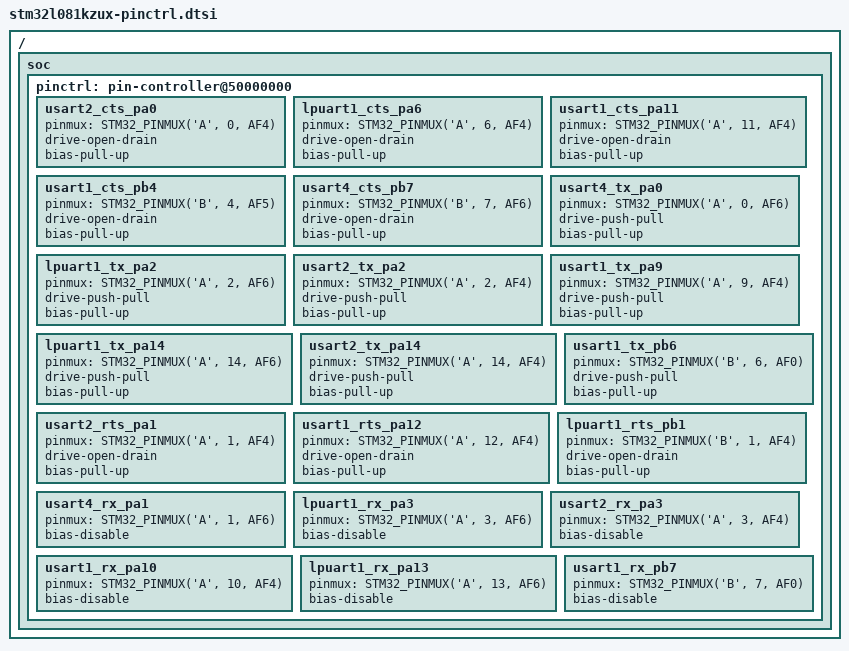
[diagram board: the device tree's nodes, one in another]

/*
 * NOTE: Autogenerated file using stm32_pinctrl_gen.py
 *
 * SPDX-License-Identifier: Apache-2.0
 */

#include <dt-bindings/pinctrl/stm32-pinctrl.h>

/ {
	soc {
		pinctrl: pin-controller@50000000 {
			/* UART_CTS */
			usart2_cts_pa0: usart2_cts_pa0 {
				pinmux = <STM32_PINMUX('A', 0, AF4)>;
				drive-open-drain;
				bias-pull-up;
			};

			lpuart1_cts_pa6: lpuart1_cts_pa6 {
				pinmux = <STM32_PINMUX('A', 6, AF4)>;
				drive-open-drain;
				bias-pull-up;
			};

			lpuart1_cts_pa6: lpuart1_cts_pa6 {
				pinmux = <STM32_PINMUX('A', 6, AF4)>;
				drive-open-drain;
				bias-pull-up;
			};

			usart1_cts_pa11: usart1_cts_pa11 {
				pinmux = <STM32_PINMUX('A', 11, AF4)>;
				drive-open-drain;
				bias-pull-up;
			};

			usart1_cts_pb4: usart1_cts_pb4 {
				pinmux = <STM32_PINMUX('B', 4, AF5)>;
				drive-open-drain;
				bias-pull-up;
			};

			usart4_cts_pb7: usart4_cts_pb7 {
				pinmux = <STM32_PINMUX('B', 7, AF6)>;
				drive-open-drain;
				bias-pull-up;
			};


			/* UART_TX */
			usart4_tx_pa0: usart4_tx_pa0 {
				pinmux = <STM32_PINMUX('A', 0, AF6)>;
				drive-push-pull;
				bias-pull-up;
			};

			lpuart1_tx_pa2: lpuart1_tx_pa2 {
				pinmux = <STM32_PINMUX('A', 2, AF6)>;
				drive-push-pull;
				bias-pull-up;
			};

			lpuart1_tx_pa2: lpuart1_tx_pa2 {
				pinmux = <STM32_PINMUX('A', 2, AF6)>;
				drive-push-pull;
				bias-pull-up;
			};

			usart2_tx_pa2: usart2_tx_pa2 {
				pinmux = <STM32_PINMUX('A', 2, AF4)>;
				drive-push-pull;
				bias-pull-up;
			};

			usart1_tx_pa9: usart1_tx_pa9 {
				pinmux = <STM32_PINMUX('A', 9, AF4)>;
				drive-push-pull;
				bias-pull-up;
			};

			lpuart1_tx_pa14: lpuart1_tx_pa14 {
				pinmux = <STM32_PINMUX('A', 14, AF6)>;
				drive-push-pull;
				bias-pull-up;
			};

			lpuart1_tx_pa14: lpuart1_tx_pa14 {
				pinmux = <STM32_PINMUX('A', 14, AF6)>;
				drive-push-pull;
				bias-pull-up;
			};

			usart2_tx_pa14: usart2_tx_pa14 {
				pinmux = <STM32_PINMUX('A', 14, AF4)>;
				drive-push-pull;
				bias-pull-up;
			};

			usart1_tx_pb6: usart1_tx_pb6 {
				pinmux = <STM32_PINMUX('B', 6, AF0)>;
				drive-push-pull;
				bias-pull-up;
			};


			/* UART_RTS */
			usart2_rts_pa1: usart2_rts_pa1 {
				pinmux = <STM32_PINMUX('A', 1, AF4)>;
				drive-open-drain;
				bias-pull-up;
			};

			usart1_rts_pa12: usart1_rts_pa12 {
				pinmux = <STM32_PINMUX('A', 12, AF4)>;
				drive-open-drain;
				bias-pull-up;
			};

			lpuart1_rts_pb1: lpuart1_rts_pb1 {
				pinmux = <STM32_PINMUX('B', 1, AF4)>;
				drive-open-drain;
				bias-pull-up;
			};

			lpuart1_rts_pb1: lpuart1_rts_pb1 {
				pinmux = <STM32_PINMUX('B', 1, AF4)>;
				drive-open-drain;
				bias-pull-up;
			};


			/* UART_RX */
			usart4_rx_pa1: usart4_rx_pa1 {
				pinmux = <STM32_PINMUX('A', 1, AF6)>;
				bias-disable;
			};

			lpuart1_rx_pa3: lpuart1_rx_pa3 {
				pinmux = <STM32_PINMUX('A', 3, AF6)>;
				bias-disable;
			};

			lpuart1_rx_pa3: lpuart1_rx_pa3 {
				pinmux = <STM32_PINMUX('A', 3, AF6)>;
				bias-disable;
			};

			usart2_rx_pa3: usart2_rx_pa3 {
				pinmux = <STM32_PINMUX('A', 3, AF4)>;
				bias-disable;
			};

			usart1_rx_pa10: usart1_rx_pa10 {
				pinmux = <STM32_PINMUX('A', 10, AF4)>;
				bias-disable;
			};

			lpuart1_rx_pa13: lpuart1_rx_pa13 {
				pinmux = <STM32_PINMUX('A', 13, AF6)>;
				bias-disable;
			};

			lpuart1_rx_pa13: lpuart1_rx_pa13 {
				pinmux = <STM32_PINMUX('A', 13, AF6)>;
				bias-disable;
			};

			usart1_rx_pb7: usart1_rx_pb7 {
				pinmux = <STM32_PINMUX('B', 7, AF0)>;
				bias-disable;
			};

		};
	};
};
